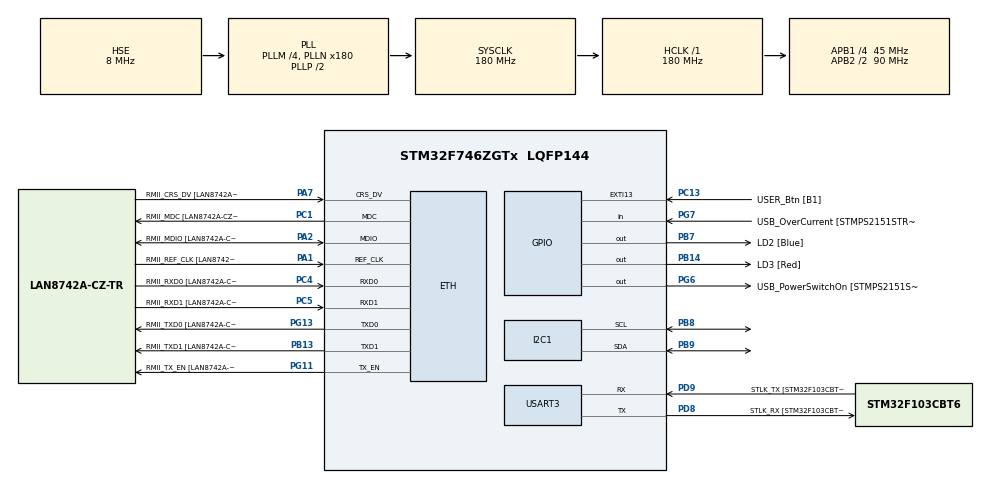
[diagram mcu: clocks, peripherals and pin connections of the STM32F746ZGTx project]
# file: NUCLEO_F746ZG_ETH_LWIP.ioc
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CORTEX_M7.CPU_DCache=Enabled
CORTEX_M7.CPU_ICache=Enabled
ETH.MACAddr=80\:34\:28\:74\:A5\:CB
ETH.MediaInterface=HAL_ETH_RMII_MODE
ETH.RxBuffLen=1524
FREERTOS.Tasks01=defaultTask,0,1024,StartDefaultTask,Default,NULL,Dynamic,NULL,NULL
FREERTOS.configGENERATE_RUN_TIME_STATS=1
FREERTOS.configRECORD_STACK_HIGH_ADDRESS=1
FREERTOS.configUSE_NEWLIB_REENTRANT=1
I2C1.Timing=0xC0000E12
LWIP.BSP.number=1
LWIP.CMSIS_VERSION-Enabled=1
LWIP.GATEWAY_ADDRESS=192.168.001.001
LWIP.IP_ADDRESS=192.168.001.120
LWIP.LWIP_DHCP=0
LWIP.NETMASK_ADDRESS=255.255.255.000
LWIP.Version=v2.1.2_Cube
LWIP0.BSP.STBoard=false
LWIP0.BSP.api=BSP_COMPONENT_DRIVER
LWIP0.BSP.component=LAN8742
LWIP0.BSP.instance=LAN8742
LWIP0.BSP.name=Driver_PHY
LWIP0.BSP.semaphore=S_LAN8742
LWIP0.BSP.solution=LAN8742
Mcu.Family=STM32F7
Mcu.Name=STM32F746ZGTx
Mcu.Package=LQFP144
NVIC.ETH_IRQn=true\:5\:0\:false\:false\:true\:true\:true\:true\:true
NVIC.PriorityGroup=NVIC_PRIORITYGROUP_4
NVIC.TIM6_DAC_IRQn=true\:15\:0\:false\:false\:true\:false\:false\:true\:true
NVIC.TimeBase=TIM6_DAC_IRQn
NVIC.TimeBaseIP=TIM6
PA1.GPIO_Label=RMII_REF_CLK [LAN8742A-CZ-TR_REFCLK0]
PA1.Mode=RMII
PA1.Signal=ETH_REF_CLK
PA10.GPIO_Label=USB_ID
PA10.Signal=USB_OTG_FS_ID
PA11.GPIO_Label=USB_DM
PA11.Signal=USB_OTG_FS_DM
PA12.GPIO_Label=USB_DP
PA12.Signal=USB_OTG_FS_DP
PA13.GPIO_Label=TMS
PA13.Mode=Serial_Wire
PA13.Signal=SYS_JTMS-SWDIO
PA14.GPIO_Label=TCK
PA14.Mode=Serial_Wire
PA14.Signal=SYS_JTCK-SWCLK
PA2.GPIO_Label=RMII_MDIO [LAN8742A-CZ-TR_MDIO]
PA2.Mode=RMII
PA2.Signal=ETH_MDIO
PA7.GPIO_Label=RMII_CRS_DV [LAN8742A-CZ-TR_CRS_DV]
PA7.Mode=RMII
PA7.Signal=ETH_CRS_DV
PA9.GPIO_Label=USB_VBUS
PA9.Signal=USB_OTG_FS_VBUS
PB13.GPIO_Label=RMII_TXD1 [LAN8742A-CZ-TR_TXD1]
PB13.Mode=RMII
PB13.Signal=ETH_TXD1
PB14.GPIO_Label=LD3 [Red]
PB14.Signal=GPIO_Output
PB3.GPIO_Label=SW0
PB3.Signal=SYS_JTDO-SWO
PB7.GPIO_Label=LD2 [Blue]
PB7.Signal=GPIO_Output
PB8.Mode=I2C
PB8.Signal=I2C1_SCL
PB9.Mode=I2C
PB9.Signal=I2C1_SDA
PC1.GPIO_Label=RMII_MDC [LAN8742A-CZ-TR_MDC]
PC1.Mode=RMII
PC1.Signal=ETH_MDC
PC13.GPIO_Label=USER_Btn [B1]
PC13.Signal=GPXTI13
PC14/OSC32_IN.Mode=LSE-External-Oscillator
PC14/OSC32_IN.Signal=RCC_OSC32_IN
PC15/OSC32_OUT.Mode=LSE-External-Oscillator
PC15/OSC32_OUT.Signal=RCC_OSC32_OUT
PC4.GPIO_Label=RMII_RXD0 [LAN8742A-CZ-TR_RXD0]
PC4.Mode=RMII
PC4.Signal=ETH_RXD0
PC5.GPIO_Label=RMII_RXD1 [LAN8742A-CZ-TR_RXD1]
PC5.Mode=RMII
PC5.Signal=ETH_RXD1
PD8.GPIO_Label=STLK_RX [STM32F103CBT6_PA3]
PD8.GPIO_PuPd=GPIO_PULLUP
PD8.Mode=Asynchronous
PD8.Signal=USART3_TX
PD9.GPIO_Label=STLK_TX [STM32F103CBT6_PA2]
PD9.GPIO_PuPd=GPIO_PULLUP
PD9.Mode=Asynchronous
PD9.Signal=USART3_RX
PG11.GPIO_Label=RMII_TX_EN [LAN8742A-CZ-TR_TXEN]
PG11.Mode=RMII
PG11.Signal=ETH_TX_EN
PG13.GPIO_Label=RMII_TXD0 [LAN8742A-CZ-TR_TXD0]
PG13.Mode=RMII
PG13.Signal=ETH_TXD0
PG6.GPIO_Label=USB_PowerSwitchOn [STMPS2151STR_EN]
PG6.Signal=GPIO_Output
PG7.GPIO_Label=USB_OverCurrent [STMPS2151STR_FAULT]
PG7.Signal=GPIO_Input
PH0/OSC_IN.GPIO_Label=MCO [STM32F103CBT6_PA8]
PH0/OSC_IN.Mode=HSE-External-Clock-Source
PH0/OSC_IN.Signal=RCC_OSC_IN
PH1/OSC_OUT.Mode=HSE-External-Clock-Source
PH1/OSC_OUT.Signal=RCC_OSC_OUT
ProjectManager.HeapSize=0x200
ProjectManager.StackSize=0x400
ProjectManager.TargetToolchain=STM32CubeIDE
RCC.48MHZClocksFreq_Value=24000000
RCC.AHBFreq_Value=180000000
RCC.APB1CLKDivider=RCC_HCLK_DIV4
RCC.APB1Freq_Value=45000000
RCC.APB1TimFreq_Value=90000000
RCC.APB2CLKDivider=RCC_HCLK_DIV2
RCC.APB2Freq_Value=90000000
RCC.APB2TimFreq_Value=180000000
RCC.CortexFreq_Value=180000000
RCC.HCLKFreq_Value=180000000
RCC.HSE_VALUE=8000000
RCC.HSI_VALUE=16000000
RCC.PLLM=4
RCC.PLLMUL=RCC_PLL_MUL9
RCC.PLLN=180
RCC.PLLQ=3
RCC.PLLSourceVirtual=RCC_PLLSOURCE_HSE
RCC.PRESCALERUSB=RCC_USBCLKSOURCE_PLL_DIV1_5
RCC.SYSCLKFreq_VALUE=180000000
RCC.SYSCLKSource=RCC_SYSCLKSOURCE_PLLCLK
RCC.SYSCLKSourceVirtual=RCC_SYSCLKSOURCE_PLLCLK
RCC.USBFreq_Value=120000000
RCC.VCOOutputFreq_Value=360000000
USART3.VirtualMode-Asynchronous=VM_ASYNC
VP_FREERTOS_VS_CMSIS_V1.Mode=CMSIS_V1
VP_LWIP_VS_Enabled.Mode=Enabled
VP_SYS_VS_tim6.Mode=TIM6
board=NUCLEO-F746ZG

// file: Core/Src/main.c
/* USER CODE BEGIN Header */
/**
  ******************************************************************************
  * @file           : main.c
  * @brief          : Main program body
  ******************************************************************************
  * @attention
  *
  * Copyright (c) 2025 STMicroelectronics.
  * All rights reserved.
  *
  * This software is licensed under terms that can be found in the LICENSE file
  * in the root directory of this software component.
  * If no LICENSE file comes with this software, it is provided AS-IS.
  *
  ******************************************************************************
  */
/* USER CODE END Header */
#include "main.h"
#include "cmsis_os.h"
#include "lwip.h"

/* USER CODE BEGIN Includes */
#include "lwipopts.h"
#include "lwip/netif.h"
#include "lwip/tcpip.h"
#include "ethernetif.h"
#include "lwip/api.h"
#include "stm32f7xx_hal_eth.h"
#include "lwip/init.h"
#include <string.h>
#include <stdio.h>

/* USER CODE END Includes */

I2C_HandleTypeDef hi2c1;

UART_HandleTypeDef huart3;

osThreadId defaultTaskHandle;
/* USER CODE BEGIN PV */
/* Network interface structure */
//struct netif gnetif;

/* Semaphore to signal Ethernet Link state update */
osSemaphoreId Netif_IRQSemaphore = NULL;

/* USER CODE END PV */

void SystemClock_Config(void);
static void MX_GPIO_Init(void);
static void MX_I2C1_Init(void);
static void MX_USART3_UART_Init(void);
void StartDefaultTask(void const * argument);

int main(void)
{

  /* Enable the CPU Cache */

  /* Enable I-Cache---------------------------------------------------------*/
  SCB_EnableICache();

  /* Enable D-Cache---------------------------------------------------------*/
  SCB_EnableDCache();

  /* MCU Configuration--------------------------------------------------------*/

  /* Reset of all peripherals, Initializes the Flash interface and the Systick. */
  HAL_Init();

  /* Configure the system clock */
  SystemClock_Config();

  /* Initialize all configured peripherals */
  MX_GPIO_Init();
  MX_I2C1_Init();
  MX_USART3_UART_Init();

  /* Create the thread(s) */
  /* definition and creation of defaultTask */
  osThreadDef(defaultTask, StartDefaultTask, osPriorityNormal, 0, 1024);
  defaultTaskHandle = osThreadCreate(osThread(defaultTask), NULL);

  /* Start scheduler */
  osKernelStart();

  /* We should never get here as control is now taken by the scheduler */

  /* Infinite loop */
  while (1)
  {

  }
}

void SystemClock_Config(void)
{
  RCC_OscInitTypeDef RCC_OscInitStruct = {0};
  RCC_ClkInitTypeDef RCC_ClkInitStruct = {0};

  /** Configure LSE Drive Capability
  */
  HAL_PWR_EnableBkUpAccess();

  /** Configure the main internal regulator output voltage
  */
  __HAL_RCC_PWR_CLK_ENABLE();
  __HAL_PWR_VOLTAGESCALING_CONFIG(PWR_REGULATOR_VOLTAGE_SCALE1);

  /** Initializes the RCC Oscillators according to the specified parameters
  * in the RCC_OscInitTypeDef structure.
  */
  RCC_OscInitStruct.OscillatorType = RCC_OSCILLATORTYPE_HSE;
  RCC_OscInitStruct.HSEState = RCC_HSE_BYPASS;
  RCC_OscInitStruct.PLL.PLLState = RCC_PLL_ON;
  RCC_OscInitStruct.PLL.PLLSource = RCC_PLLSOURCE_HSE;
  RCC_OscInitStruct.PLL.PLLM = 4;
  RCC_OscInitStruct.PLL.PLLN = 180;
  RCC_OscInitStruct.PLL.PLLP = RCC_PLLP_DIV2;
  RCC_OscInitStruct.PLL.PLLQ = 3;
  if (HAL_RCC_OscConfig(&RCC_OscInitStruct) != HAL_OK)
  {
    Error_Handler();
  }

  /** Initializes the CPU, AHB and APB buses clocks
  */
  RCC_ClkInitStruct.ClockType = RCC_CLOCKTYPE_HCLK|RCC_CLOCKTYPE_SYSCLK
                              |RCC_CLOCKTYPE_PCLK1|RCC_CLOCKTYPE_PCLK2;
  RCC_ClkInitStruct.SYSCLKSource = RCC_SYSCLKSOURCE_PLLCLK;
  RCC_ClkInitStruct.AHBCLKDivider = RCC_SYSCLK_DIV1;
  RCC_ClkInitStruct.APB1CLKDivider = RCC_HCLK_DIV4;
  RCC_ClkInitStruct.APB2CLKDivider = RCC_HCLK_DIV2;

  if (HAL_RCC_ClockConfig(&RCC_ClkInitStruct, FLASH_LATENCY_5) != HAL_OK)
  {
    Error_Handler();
  }
}

static void MX_I2C1_Init(void)
{

  hi2c1.Instance = I2C1;
  hi2c1.Init.Timing = 0xC0000E12;
  hi2c1.Init.OwnAddress1 = 0;
  hi2c1.Init.AddressingMode = I2C_ADDRESSINGMODE_7BIT;
  hi2c1.Init.DualAddressMode = I2C_DUALADDRESS_DISABLE;
  hi2c1.Init.OwnAddress2 = 0;
  hi2c1.Init.OwnAddress2Masks = I2C_OA2_NOMASK;
  hi2c1.Init.GeneralCallMode = I2C_GENERALCALL_DISABLE;
  hi2c1.Init.NoStretchMode = I2C_NOSTRETCH_DISABLE;
  if (HAL_I2C_Init(&hi2c1) != HAL_OK)
  {
    Error_Handler();
  }

  /** Configure Analogue filter
  */
  if (HAL_I2CEx_ConfigAnalogFilter(&hi2c1, I2C_ANALOGFILTER_ENABLE) != HAL_OK)
  {
    Error_Handler();
  }

  /** Configure Digital filter
  */
  if (HAL_I2CEx_ConfigDigitalFilter(&hi2c1, 0) != HAL_OK)
  {
    Error_Handler();
  }

}

static void MX_USART3_UART_Init(void)
{

  huart3.Instance = USART3;
  huart3.Init.BaudRate = 115200;
  huart3.Init.WordLength = UART_WORDLENGTH_8B;
  huart3.Init.StopBits = UART_STOPBITS_1;
  huart3.Init.Parity = UART_PARITY_NONE;
  huart3.Init.Mode = UART_MODE_TX_RX;
  huart3.Init.HwFlowCtl = UART_HWCONTROL_NONE;
  huart3.Init.OverSampling = UART_OVERSAMPLING_16;
  huart3.Init.OneBitSampling = UART_ONE_BIT_SAMPLE_DISABLE;
  huart3.AdvancedInit.AdvFeatureInit = UART_ADVFEATURE_NO_INIT;
  if (HAL_UART_Init(&huart3) != HAL_OK)
  {
    Error_Handler();
  }

}

static void MX_GPIO_Init(void)
{
  GPIO_InitTypeDef GPIO_InitStruct = {0};

  /* GPIO Ports Clock Enable */
  __HAL_RCC_GPIOC_CLK_ENABLE();
  __HAL_RCC_GPIOH_CLK_ENABLE();
  __HAL_RCC_GPIOA_CLK_ENABLE();
  __HAL_RCC_GPIOB_CLK_ENABLE();
  __HAL_RCC_GPIOD_CLK_ENABLE();
  __HAL_RCC_GPIOG_CLK_ENABLE();

  /*Configure GPIO pin Output Level */
  HAL_GPIO_WritePin(GPIOB, LD3_Pin|LD2_Pin, GPIO_PIN_RESET);

  /*Configure GPIO pin Output Level */
  HAL_GPIO_WritePin(USB_PowerSwitchOn_GPIO_Port, USB_PowerSwitchOn_Pin, GPIO_PIN_RESET);

  /*Configure GPIO pin : USER_Btn_Pin */
  GPIO_InitStruct.Pin = USER_Btn_Pin;
  GPIO_InitStruct.Mode = GPIO_MODE_IT_RISING;
  GPIO_InitStruct.Pull = GPIO_NOPULL;
  HAL_GPIO_Init(USER_Btn_GPIO_Port, &GPIO_InitStruct);

  /*Configure GPIO pins : LD3_Pin LD2_Pin */
  GPIO_InitStruct.Pin = LD3_Pin|LD2_Pin;
  GPIO_InitStruct.Mode = GPIO_MODE_OUTPUT_PP;
  GPIO_InitStruct.Pull = GPIO_NOPULL;
  GPIO_InitStruct.Speed = GPIO_SPEED_FREQ_LOW;
  HAL_GPIO_Init(GPIOB, &GPIO_InitStruct);

  /*Configure GPIO pin : USB_PowerSwitchOn_Pin */
  GPIO_InitStruct.Pin = USB_PowerSwitchOn_Pin;
  GPIO_InitStruct.Mode = GPIO_MODE_OUTPUT_PP;
  GPIO_InitStruct.Pull = GPIO_NOPULL;
  GPIO_InitStruct.Speed = GPIO_SPEED_FREQ_LOW;
  HAL_GPIO_Init(USB_PowerSwitchOn_GPIO_Port, &GPIO_InitStruct);

  /*Configure GPIO pin : USB_OverCurrent_Pin */
  GPIO_InitStruct.Pin = USB_OverCurrent_Pin;
  GPIO_InitStruct.Mode = GPIO_MODE_INPUT;
  GPIO_InitStruct.Pull = GPIO_NOPULL;
  HAL_GPIO_Init(USB_OverCurrent_GPIO_Port, &GPIO_InitStruct);

  /*Configure GPIO pin : USB_VBUS_Pin */
  GPIO_InitStruct.Pin = USB_VBUS_Pin;
  GPIO_InitStruct.Mode = GPIO_MODE_INPUT;
  GPIO_InitStruct.Pull = GPIO_NOPULL;
  HAL_GPIO_Init(USB_VBUS_GPIO_Port, &GPIO_InitStruct);

  /*Configure GPIO pins : USB_ID_Pin USB_DM_Pin USB_DP_Pin */
  GPIO_InitStruct.Pin = USB_ID_Pin|USB_DM_Pin|USB_DP_Pin;
  GPIO_InitStruct.Mode = GPIO_MODE_AF_PP;
  GPIO_InitStruct.Pull = GPIO_NOPULL;
  GPIO_InitStruct.Speed = GPIO_SPEED_FREQ_VERY_HIGH;
  GPIO_InitStruct.Alternate = GPIO_AF10_OTG_FS;
  HAL_GPIO_Init(GPIOA, &GPIO_InitStruct);

}

/* USER CODE BEGIN 4 */
int putchar(int ch)
{
    HAL_UART_Transmit(&huart3,(uint8_t *)&ch,1,1);
    return ch;
}
/* USER CODE END 4 */

void StartDefaultTask(void const * argument)
{
    /* init code for LWIP */
    MX_LWIP_Init();
    // Simple TCP Client

    // Declaring data structures
    ip_addr_t server_ip;
    err_t status;
    struct netconn *conn; // pointer to hold connection data

    char buffer[256];  // Create a buffer to store formatted strings

    while (!netif_is_up(netif_default)) {
        snprintf(buffer, sizeof(buffer), "Waiting for network...\r\n");
        printf("%s", buffer);  // Output the formatted string
        osDelay(500);
    }

    snprintf(buffer, sizeof(buffer), "Network is up!\r\n");
    printf("%s", buffer);  // Output the formatted string

    conn = netconn_new(NETCONN_TCP);
    if (conn == NULL) {
        snprintf(buffer, sizeof(buffer), "Failed to create connection.\r\n");
        printf("%s", buffer);  // Output the formatted string
        return;
    }

    // Set server IP address (192.168.31.166)
    IP4_ADDR(&server_ip, 192, 168, 31, 166);

    // Connect to the TCP server on port 8000
    snprintf(buffer, sizeof(buffer), "Connecting to server...\r\n");
    printf("%s", buffer);  // Output the formatted string
    status = netconn_connect(conn, &server_ip, 8000);

    if (status == ERR_OK) {
        snprintf(buffer, sizeof(buffer), "Connected to server!\r\n");
        printf("%s", buffer);  // Output the formatted string

        for (int i = 0; i < 5; i++) {
            snprintf(buffer, sizeof(buffer), "Sending JSON data to server...\r\n");
            printf("%s", buffer);  // Output the formatted string

            // Create JSON-formatted string
            char json_buffer[256];
            int len = snprintf(json_buffer, sizeof(json_buffer),
                               "{ \"Node ID\": %d, \"Door Status\": %s }\r\n", 1, "true");

            if (len < 0 || len >= sizeof(json_buffer)) {
                snprintf(buffer, sizeof(buffer), "Error: snprintf buffer overflow!\r\n");
                printf("%s", buffer);  // Output the formatted string
                netconn_delete(conn);
                return;
            }

            // Send JSON data
            status = netconn_write(conn, json_buffer, strlen(json_buffer), NETCONN_NOCOPY);

            if (status != ERR_OK) {
                snprintf(buffer, sizeof(buffer), "Failed to send data!\r\n");
                printf("%s", buffer);  // Output the formatted string
                netconn_delete(conn);
                return;
            } else {
                snprintf(buffer, sizeof(buffer), "Data sent successfully!\r\n");
                printf("%s", buffer);  // Output the formatted string
            }

            osDelay(1000); // Wait for 1 second
        }

        // Close and delete connection
        netconn_close(conn);
        netconn_delete(conn);
        snprintf(buffer, sizeof(buffer), "Connection closed.\r\n");
        printf("%s", buffer);  // Output the formatted string
    } else {
        snprintf(buffer, sizeof(buffer), "Could not connect to server.\r\n");
        printf("%s", buffer);  // Output the formatted string
        netconn_delete(conn);
    }

    for(;;) {
    }
}

void HAL_TIM_PeriodElapsedCallback(TIM_HandleTypeDef *htim)
{
  if (htim->Instance == TIM6) {
    HAL_IncTick();
  }
}

void Error_Handler(void)
{
  __disable_irq();
  while (1)
  {
  }
}
